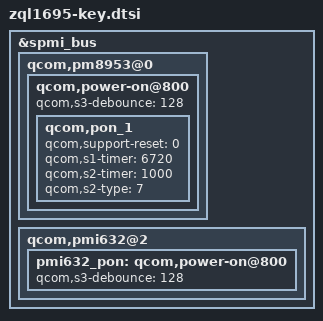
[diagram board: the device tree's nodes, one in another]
&spmi_bus {
	qcom,pm8953@0{
		qcom,power-on@800 {
			qcom,s3-debounce = <128>;
			qcom,pon_1 {
				/* HS60 code modify for P191009-02696 by liufurong at 20191028 start */
				qcom,support-reset = <0>;
				/* HS60 code modify for P191009-02696 by liufurong at 20191028 end */
				qcom,s1-timer = <6720>;
				qcom,s2-timer = <1000>;
				qcom,s2-type = <7>;
			};
		};
	};
	qcom,pmi632@2 {
		pmi632_pon: qcom,power-on@800 {
			qcom,s3-debounce = <128>;
		};
	};
};
